# Polarfire SoC register map
Vendor: Microchip; File version: 1.0
CPU: Microchip PolarFire SoC 1.0, little endian
Registers are 32-bit, read-write, reset 0x0 unless marked. A register's access mark holds for its fields unless they carry their own. Offsets are from the block's base; [hi:lo] are bit positions; {n}, {i} and the like mark numbered series.

## ATHENA — ATHENA Controller
Base 0x22006000
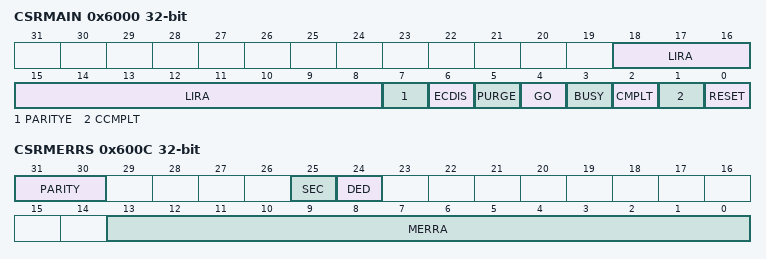
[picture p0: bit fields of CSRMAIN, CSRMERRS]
0x6000 CSRMAIN — Main CSR
  [18:8] LIRA — LIR start address
  [7] PARITYE ro — Parity error
  [6] ECDIS ro — Elliptic curve instruction disable bit (E5200/6400 only)
  [5] PURGE — Soft purge command bit
  [4] GO — Start computation command bit
  [3] BUSY ro — Busy status bit
  [2] CMPLT ro — Computation complete status bit
  [1] CCMPLT — Write-only clear CMPLT flag bit
  [0] RESET — Soft reset command bit
0x600C CSRMERRS — Memory error status register
  [31:30] PARITY ro — Parity capability field
  [25] SEC — LIR/FPR/TSR/MMR/BER single error correct status flag
  [24] DED ro — LIR/FPR/TSR/MMR/BER double error detect status flag
  [13:0] MERRA ro — Memory error word address
0x6010 CSRMERRV ro — Memory error value register
  [31:0] CSRMERRV — The CSRMERRV is a single 32-bit read-only register that provides the error correction mask output of the ECC logic when either SEC or DED is asserted by the ECC logic if present (PARITYC equal to 102 or 112). If ECC logic is not present (PARITYC equal to 012 or 002), then this field will always be zero.
0x6014 CSRMERRT0 — Memory Error Handling Test Register
  [31:0] CSRMERRT0 — The CSRMERRT0-1 memory error handling test register is a read-write register that is used to inject errors into memory writes in order to enable testing of error detection and/or correction logic
0x6018 CSRMERRT1 — Memory Error Handling Test Register
  [31:0] CSRMERRT1 — The CSRMERRT0-1 memory error handling test register is a read-write register that is used to inject errors into memory writes in order to enable testing of error detection and/or correction logic

## IOSCBCFG — IOSCBCFG Controller
Base 0x37080000
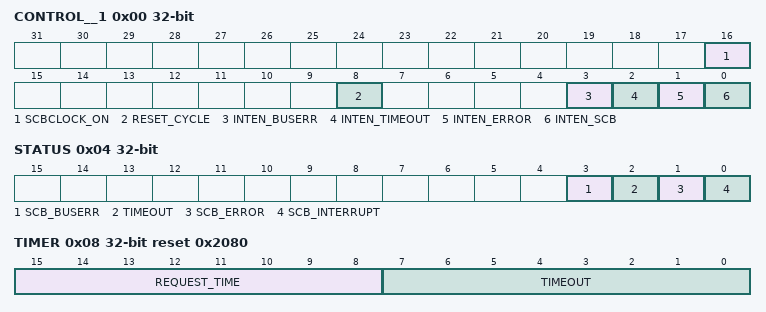
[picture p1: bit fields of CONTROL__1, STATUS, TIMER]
0x00 CONTROL__1
  [16] SCBCLOCK_ON — Setting this requests PFC to turn on the SCB clock permanently
  [8] RESET_CYCLE — Writing a '1' to the bit will cause a reset off the internal FSMS. Once set it will stay asserted until the reset cycle completes when it will be cleared. This may take several clock cycles depending on relative speeds of the SCB and AHB clocks.
  [3] INTEN_BUSERR — Enables interrupt when SCB bus error detected
  [2] INTEN_TIMEOUT — Enables interrupt when timeout occurs
  [1] INTEN_ERROR — Enables interrupt when SCB error asserted
  [0] INTEN_SCB — Enables interrupt when SCB Interrupt asserted
0x04 STATUS ro
  [3] SCB_BUSERR — Indicated that an SCB bus error (parity) was detected. Is cleared by initiating FSM reset cycle (Control register bit 16)
  [2] TIMEOUT — Indicated that the SCB access timed out. Is cleared by initiating FSM reset cycle (Control register bit 16)
  [1] SCB_ERROR — Indicates that the SCB error was asserted. Is cleared by initiating FSM reset cycle (Control register bit 16)
  [0] SCB_INTERRUPT — Indicated SCB interrupt active. Is cleared by clearing the SCB interrupt source
0x08 TIMER reset 0x2080
  [15:8] REQUEST_TIME — Sets how long SCB request is held active after SCB bus granted. Allows SCB bus mastership to maintained across multiple SCB access cycles
  [7:0] TIMEOUT — Set the timeout for an SCB access in CPU cycles.

## IOSCB_PLL_MSS — IOSCB MSS PLL Controller
Base 0x3E001000
Same registers: IOSCB_PLL_DDR 0x3E010000, IOSCB_PLL_SGMII 0x3E080000
0x00 SOFT_RESET
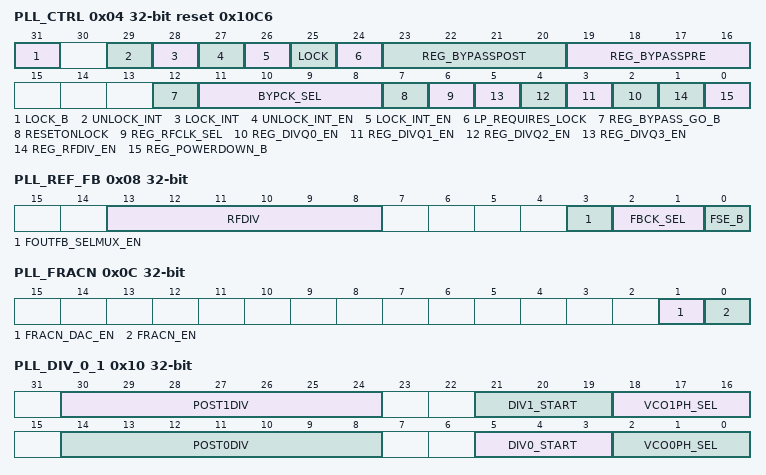
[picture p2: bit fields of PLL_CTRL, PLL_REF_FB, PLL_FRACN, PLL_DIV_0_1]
0x04 PLL_CTRL reset 0x10C6 — PLL control register
  [31] LOCK_B ro
  [29] UNLOCK_INT wo write-1-clears — Write 1 to clear unlock interrupt. This is a write-1-to-clear (SW1C) bit.
  [28] LOCK_INT wo write-1-clears — Write 1 to clear lock interrupt. This is a write-1-to-clear (SW1C) bit.
  [27] UNLOCK_INT_EN
  [26] LOCK_INT_EN
  [25] LOCK ro
  [24] LP_REQUIRES_LOCK
  [23:20] REG_BYPASSPOST
  [19:16] REG_BYPASSPRE
  [12] REG_BYPASS_GO_B
  [11:8] BYPCK_SEL
  [7] RESETONLOCK
  [6] REG_RFCLK_SEL
  [n+2] REG_DIVQ{n}_EN (n=0..3)
  [1] REG_RFDIV_EN
  [0] REG_POWERDOWN_B
0x08 PLL_REF_FB — PLL reference feedback register
  [13:8] RFDIV, [3] FOUTFB_SELMUX_EN, [2:1] FBCK_SEL, [0] FSE_B
0x0C PLL_FRACN — PLL fractional N register
  [1] FRACN_DAC_EN, [0] FRACN_EN
0x10 PLL_DIV_0_1 — PLL divider 0-1 register
  [30:24] POST1DIV, [21:19] DIV1_START, [18:16] VCO1PH_SEL ro, [14:8] POST0DIV, [5:3] DIV0_START, [2:0] VCO0PH_SEL ro
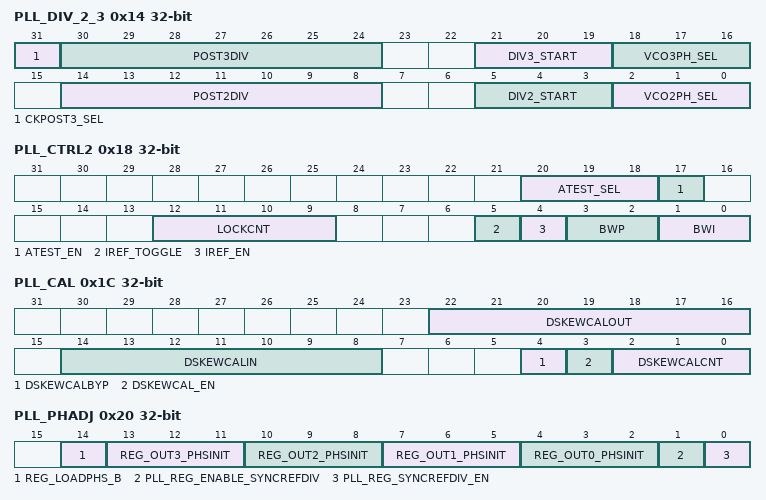
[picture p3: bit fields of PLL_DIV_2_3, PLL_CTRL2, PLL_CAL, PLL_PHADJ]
0x14 PLL_DIV_2_3 — PLL divider 2-3 register
  [31] CKPOST3_SEL, [30:24] POST3DIV, [21:19] DIV3_START, [18:16] VCO3PH_SEL ro, [14:8] POST2DIV, [5:3] DIV2_START, [2:0] VCO2PH_SEL ro
0x18 PLL_CTRL2 — PLL control 2 register
  [20:18] ATEST_SEL, [17] ATEST_EN, [12:9] LOCKCNT, [5] IREF_TOGGLE, [4] IREF_EN, [3:2] BWP, [1:0] BWI
0x1C PLL_CAL — PLL calibration register
  [22:16] DSKEWCALOUT ro, [14:8] DSKEWCALIN, [4] DSKEWCALBYP, [3] DSKEWCAL_EN, [2:0] DSKEWCALCNT
0x20 PLL_PHADJ — PLL phase adjust register
  [14] REG_LOADPHS_B, [3n+4:3n+2] REG_OUT{n}_PHSINIT (n=0..3), [1] PLL_REG_ENABLE_SYNCREFDIV, [0] PLL_REG_SYNCREFDIV_EN
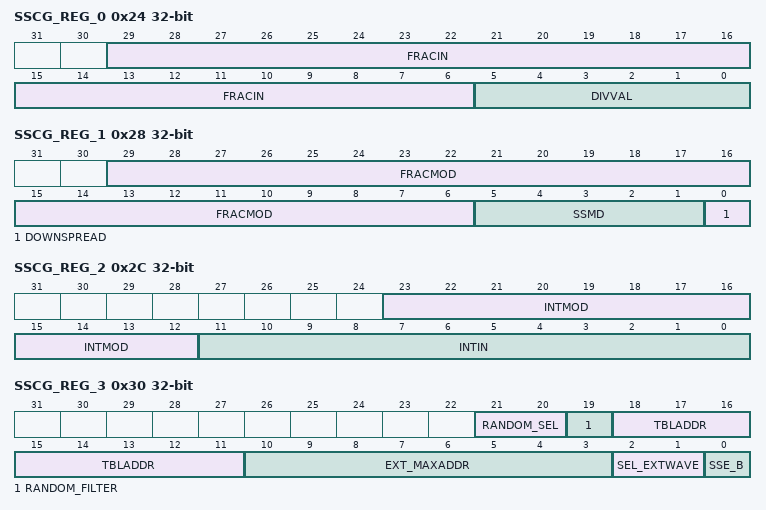
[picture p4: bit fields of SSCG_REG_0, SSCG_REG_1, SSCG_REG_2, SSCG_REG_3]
0x24 SSCG_REG_0 — SSCG register 0
  [29:6] FRACIN, [5:0] DIVVAL
0x28 SSCG_REG_1 — SSCG register 1
  [29:6] FRACMOD ro, [5:1] SSMD, [0] DOWNSPREAD
0x2C SSCG_REG_2 — SSCG register 2
  [23:12] INTMOD ro, [11:0] INTIN
0x30 SSCG_REG_3 — SSCG register 3
  [21:20] RANDOM_SEL, [19] RANDOM_FILTER, [18:11] TBLADDR ro, [10:3] EXT_MAXADDR, [2:1] SEL_EXTWAVE, [0] SSE_B
